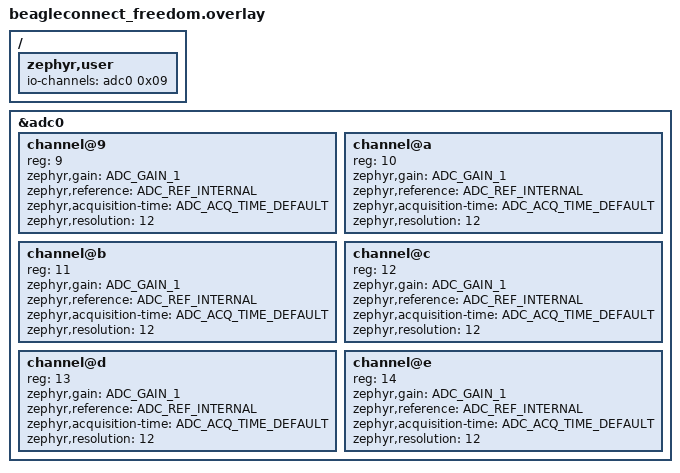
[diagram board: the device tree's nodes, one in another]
/*
 * SPDX-License-Identifier: Apache-2.0
 *
 * Copyright (c) 2024 Ayush Singh <ayush@beagleboard.org>
 */

/ {
	zephyr,user {
		/* Reading mulitple pins not possible */
		io-channels = <&adc0 0x09>;
	};
};

&adc0 {
	status = "okay";

	#address-cells = <1>;
	#size-cells = <0>;

	/* MB1 AN */
	channel@9 {
		reg = <9>;
		zephyr,gain = "ADC_GAIN_1";
		zephyr,reference = "ADC_REF_INTERNAL";
		zephyr,acquisition-time = <ADC_ACQ_TIME_DEFAULT>;
		zephyr,resolution = <12>;
	};

	/* MB2 AN */
	channel@a {
		reg = <10>;
		zephyr,gain = "ADC_GAIN_1";
		zephyr,reference = "ADC_REF_INTERNAL";
		zephyr,acquisition-time = <ADC_ACQ_TIME_DEFAULT>;
		zephyr,resolution = <12>;
	};

	/* MB1/2 SCL */
	channel@b {
		reg = <11>;
		zephyr,gain = "ADC_GAIN_1";
		zephyr,reference = "ADC_REF_INTERNAL";
		zephyr,acquisition-time = <ADC_ACQ_TIME_DEFAULT>;
		zephyr,resolution = <12>;
	};

	/* MB1/2 SDA */
	channel@c {
		reg = <12>;
		zephyr,gain = "ADC_GAIN_1";
		zephyr,reference = "ADC_REF_INTERNAL";
		zephyr,acquisition-time = <ADC_ACQ_TIME_DEFAULT>;
		zephyr,resolution = <12>;
	};

	/* MB2 CS */
	channel@d {
		reg = <13>;
		zephyr,gain = "ADC_GAIN_1";
		zephyr,reference = "ADC_REF_INTERNAL";
		zephyr,acquisition-time = <ADC_ACQ_TIME_DEFAULT>;
		zephyr,resolution = <12>;
	};

	/* MB1 CS */
	channel@e {
		reg = <14>;
		zephyr,gain = "ADC_GAIN_1";
		zephyr,reference = "ADC_REF_INTERNAL";
		zephyr,acquisition-time = <ADC_ACQ_TIME_DEFAULT>;
		zephyr,resolution = <12>;
	};
};
